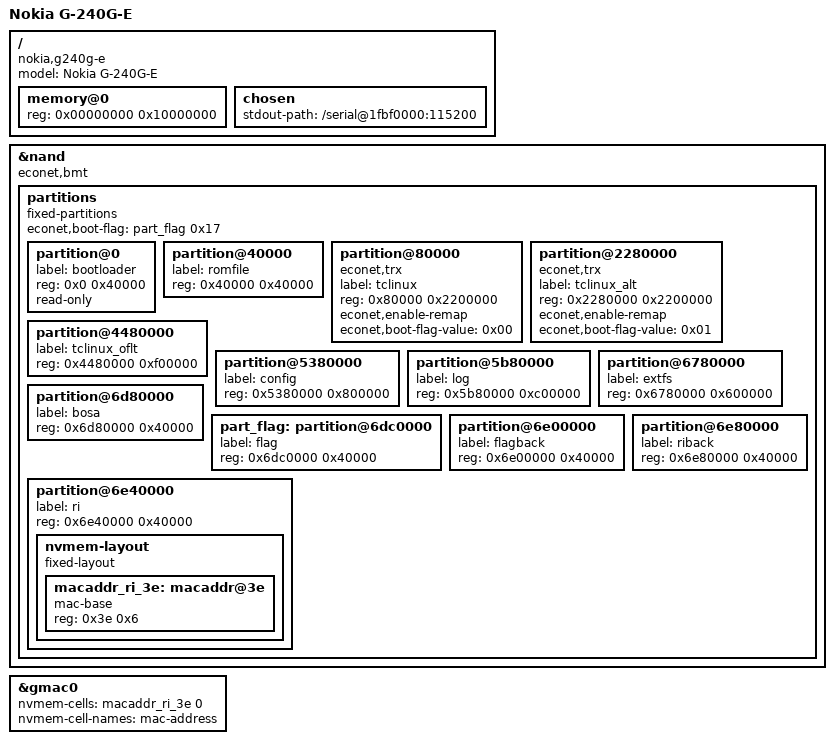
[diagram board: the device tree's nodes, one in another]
// SPDX-License-Identifier: (GPL-2.0-only OR BSD-2-Clause)
/dts-v1/;

#include "en751221.dtsi"

/ {
	model = "Nokia G-240G-E";
	compatible = "nokia,g240g-e", "econet,en751221";

	memory@0 {
		device_type = "memory";
		reg = <0x00000000 0x10000000>;
	};

	chosen {
		stdout-path = "/serial@1fbf0000:115200";
	};
};

&nand {
	status = "okay";
	econet,bmt;

	partitions {
		compatible = "fixed-partitions";
		#address-cells = <1>;
		#size-cells = <1>;

		econet,boot-flag = <&part_flag 0x17>;

		partition@0 {
			label = "bootloader";
			reg = <0x0 0x40000>;
			read-only;
		};

		partition@40000 {
			label = "romfile";
			reg = <0x40000 0x40000>;
		};

		partition@80000 {
			compatible = "econet,trx";
			label = "tclinux";
			reg = <0x80000 0x2200000>;
			econet,enable-remap;
			econet,boot-flag-value = <0x00>;
		};

		partition@2280000 {
			compatible = "econet,trx";
			label = "tclinux_alt";
			reg = <0x2280000 0x2200000>;
			econet,enable-remap;
			econet,boot-flag-value = <0x01>;
		};

		partition@4480000 {
			label = "tclinux_oflt";
			reg = <0x4480000 0xf00000>;
		};

		partition@5380000 {
			label = "config";
			reg = <0x5380000 0x800000>;
		};

		partition@5b80000 {
			label = "log";
			reg = <0x5b80000 0xc00000>;
		};

		partition@6780000 {
			label = "extfs";
			reg = <0x6780000 0x600000>;
		};

		partition@6d80000 {
			label = "bosa";
			reg = <0x6d80000 0x40000>;
		};

		part_flag: partition@6dc0000 {
			label = "flag";
			reg = <0x6dc0000 0x40000>;
		};

		partition@6e00000 {
			label = "flagback";
			reg = <0x6e00000 0x40000>;
		};

		partition@6e40000 {
			label = "ri";
			reg = <0x6e40000 0x40000>;

			nvmem-layout {
				compatible = "fixed-layout";
				#address-cells = <1>;
				#size-cells = <1>;

				macaddr_ri_3e: macaddr@3e {
					compatible = "mac-base";
					reg = <0x3e 0x6>;
					#nvmem-cell-cells = <1>;
				};
			};
		};

		partition@6e80000 {
			label = "riback";
			reg = <0x6e80000 0x40000>;
		};
	};
};

&gmac0 {
	status = "okay";
	nvmem-cells = <&macaddr_ri_3e 0>;
	nvmem-cell-names = "mac-address";
};
